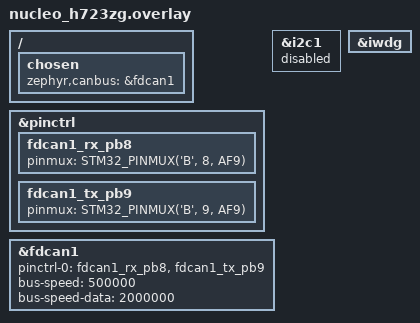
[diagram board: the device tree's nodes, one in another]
&pinctrl {
    fdcan1_rx_pb8: fdcan1_rx_pb8 {
        pinmux = <STM32_PINMUX('B', 8, AF9)>;
    };
    fdcan1_tx_pb9: fdcan1_tx_pb9 {
        pinmux = <STM32_PINMUX('B', 9, AF9)>;
    };
};

&i2c1 {
    status = "disabled";
};

&fdcan1 {
    pinctrl-0 = <&fdcan1_rx_pb8 &fdcan1_tx_pb9>;
    pinctrl-names = "default";
    status = "okay";
    bus-speed = <500000>;
    bus-speed-data = <2000000>;
};
&iwdg {
    status = "okay";
};

/ {
    chosen {
        zephyr,canbus = &fdcan1;
    };
};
